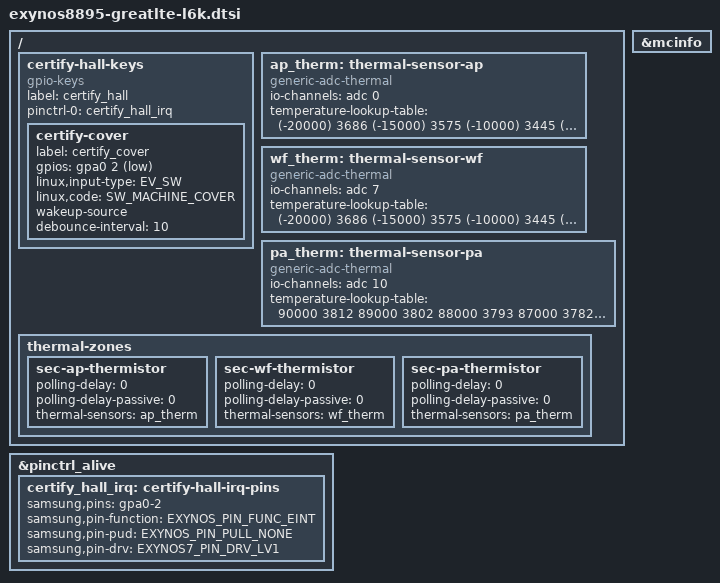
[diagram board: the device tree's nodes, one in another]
// SPDX-License-Identifier: GPL-2.0 OR BSD-3-Clause
/*
 * Samsung Galaxy Note 8 (greatlte, SM-N950N) board DT, part "l6k":
 * L6K misc I/O: certify hall, DRAM temperature trip, AP/WF/PA thermistors (L6K 4).
 *
 * Included at the end of exynos8895-greatlte.dts, after L0's nodes, in the merge
 * order of FULL_IMAGE_PLAN.md 2.2. Owner: WP-6K; no other work package edits this
 * file (plan 2.3 rule D1). A node that two parts both configure (&usi9, &usi10)
 * is written identically in both files: dtc lets the later file win on a differing
 * value, which gl-verify V-DUP reports as an error. L0's reserved-memory stays in
 * the .dts; carveout additions and flag changes are &label edits here (plan X-8).
 */

#include <dt-bindings/gpio/gpio.h>
#include <dt-bindings/input/input.h>		/* EV_SW, SW_MACHINE_COVER, 4.1 */
#include "exynos-pinctrl.h"			/* A:arch/arm64/boot/dts/exynos/exynos-pinctrl.h, pin macros of 4.1 */

/* L6K 4.1 certify hall (stock certify_hall FDT:11210-11216, D-1) */
&pinctrl_alive {
	certify_hall_irq: certify-hall-irq-pins {	/* FDT:257-263 (phandle 0x143) */
		samsung,pins = "gpa0-2";
		samsung,pin-function = <EXYNOS_PIN_FUNC_EINT>;	/* 0x0f; A:arch/arm64/boot/dts/exynos/exynos-pinctrl.h:76 */
		samsung,pin-pud = <EXYNOS_PIN_PULL_NONE>;	/* 0x00; :14 */
		samsung,pin-drv = <EXYNOS7_PIN_DRV_LV1>;	/* 0x00; :48 */
	};
};

/ {
	certify-hall-keys {
		compatible = "gpio-keys";
		label = "certify_hall";			/* stock input name S:drivers/input/certify_hall.c:249;
							   gpio-keys uses the label as input name, A:drivers/input/keyboard/gpio_keys.c:778,879 */
		pinctrl-names = "default";
		pinctrl-0 = <&certify_hall_irq>;	/* FDT:11213-11214 <0x143> */

		certify-cover {
			label = "certify_cover";
			gpios = <&gpa0 2 GPIO_ACTIVE_LOW>;	/* FDT:11215 <0x90 2 0>; attached = level 0
								   (S:drivers/input/certify_hall.c:95,127) */
			linux,input-type = <EV_SW>;		/* A:drivers/input/keyboard/gpio_keys.c:803 */
			linux,code = <SW_MACHINE_COVER>;	/* 0x10 A:include/uapi/linux/input-event-codes.h:952;
								   stock SW_CERTIFYHALL 0x1b > SW_MAX 0x11 (:954), D-1 */
			wakeup-source;				/* stock arms the wake at every suspend,
								   S:drivers/input/certify_hall.c:337; A:.../gpio_keys.c:811 */
			debounce-interval = <10>;		/* stock attach delay HZ*1/100 "10ms" (S:.../certify_hall.c:114);
								   = 2 jiffies = 8 ms at HZ 250 (IKC:448); 10 = the tree's
								   convention for this expression (L6F hall-keys);
								   A:.../gpio_keys.c:821 */
		};
	};
};

/* L6K 4.2 DRAM temperature trip (SoC node in exynos8895.dtsi) */
&mcinfo {
	status = "okay";
};

/* L6K 4.3 AP/WF/PA thermistors (stock sec_thermistor@0/@7/@10 FDT:11172-11200, D-3) */
/ {
	ap_therm: thermal-sensor-ap {
		compatible = "generic-adc-thermal";		/* A:drivers/thermal/thermal-generic-adc.c (lookup :27-56) */
		#thermal-sensor-cells = <0>;
		io-channels = <&adc 0>;				/* FDT:11177 <0x141 0x00> "adc-ap-temp" */
		io-channel-names = "sensor-channel";
		/* FDT:11175-11176, x100 to milli-degC, code falling (= L6F battery table, FDT:12188-12189) */
		temperature-lookup-table = <
			(-20000) 3686	(-15000) 3575	(-10000) 3445	(-5000) 3293
			0 3122		5000 2932	10000 2726	15000 2512
			20000 2291	25000 2048	30000 1811	35000 1586
			40000 1378	45000 1189	50000 1021	55000 887
			60000 769	65000 655	70000 558	75000 474
			80000 404	85000 345	90000 294 >;
	};

	wf_therm: thermal-sensor-wf {
		compatible = "generic-adc-thermal";
		#thermal-sensor-cells = <0>;
		io-channels = <&adc 7>;				/* FDT:11187 <0x141 0x07> "adc-wf-temp" */
		io-channel-names = "sensor-channel";
		/* FDT:11185-11186, identical to the AP table */
		temperature-lookup-table = <
			(-20000) 3686	(-15000) 3575	(-10000) 3445	(-5000) 3293
			0 3122		5000 2932	10000 2726	15000 2512
			20000 2291	25000 2048	30000 1811	35000 1586
			40000 1378	45000 1189	50000 1021	55000 887
			60000 769	65000 655	70000 558	75000 474
			80000 404	85000 345	90000 294 >;
	};

	pa_therm: thermal-sensor-pa {
		compatible = "generic-adc-thermal";
		#thermal-sensor-cells = <0>;
		io-channels = <&adc 10>;			/* FDT:11197 <0x141 0x0a> "adc-pa-temp" */
		io-channel-names = "sensor-channel";
		/* FDT:11195-11196: 111 points, code RISES with temperature; sorted by code falling, which
		 * gadc_thermal_adc_to_temp() requires (first entry with val >= code, A:...:35-38); the
		 * interpolation (:45-52) is direction-agnostic, and out-of-range codes clamp to the end
		 * points (:40-43) = stock's clamps (S:drivers/hwmon/sec_thermistor.c:175-178) */
		temperature-lookup-table = <
			90000 3812 89000 3802 88000 3793 87000 3782 86000 3773 85000 3761 84000 3752 83000 3741
			82000 3730 81000 3716 80000 3705 79000 3691 78000 3680 77000 3666 76000 3650 75000 3636
			74000 3620 73000 3607 72000 3591 71000 3573 70000 3557 69000 3538 68000 3520 67000 3502
			66000 3482 65000 3461 64000 3441 63000 3420 62000 3397 61000 3375 60000 3352 59000 3327
			58000 3302 57000 3277 56000 3249 55000 3222 54000 3195 53000 3165 52000 3136 51000 3106
			50000 3074 49000 3042 48000 3011 47000 2976 46000 2942 45000 2906 44000 2872 43000 2833
			42000 2797 41000 2758 40000 2719 39000 2678 38000 2637 37000 2596 36000 2553 35000 2510
			34000 2467 33000 2421 32000 2378 31000 2332 30000 2285 29000 2239 28000 2192 27000 2144
			26000 2096 25000 2048 24000 2000 23000 1951 22000 1902 21000 1853 20000 1804 19000 1755
			18000 1706 17000 1657 16000 1608 15000 1559 14000 1511 13000 1463 12000 1416 11000 1369
			10000 1323 9000 1277 8000 1231 7000 1187 6000 1143 5000 1100 4000 1057 3000 1016
			2000 975 1000 935 0 896 (-1000) 858 (-2000) 821 (-3000) 786 (-4000) 750 (-5000) 717
			(-6000) 684 (-7000) 651 (-8000) 621 (-9000) 591 (-10000) 562 (-11000) 534 (-12000) 507
			(-13000) 482 (-14000) 456 (-15000) 433 (-16000) 410 (-17000) 388 (-18000) 367 (-19000) 347
			(-20000) 327 >;
	};

	thermal-zones {
		/* zone type = node name (A:drivers/thermal/thermal_of.c:415), <= THERMAL_NAME_LENGTH 20
		 * (A:include/uapi/linux/thermal.h:5); stock sec device names (S:drivers/hwmon/sec_thermistor.c:55-60) */
		sec-ap-thermistor {
			polling-delay = <0>;		/* stock reads only on demand (S:drivers/hwmon/sec_thermistor.c:132-159) */
			polling-delay-passive = <0>;
			thermal-sensors = <&ap_therm>;
			/* no trips (stock had none): "No trip points found" A:drivers/thermal/thermal_of.c:395 */
		};

		sec-wf-thermistor {
			polling-delay = <0>;
			polling-delay-passive = <0>;
			thermal-sensors = <&wf_therm>;
		};

		sec-pa-thermistor {
			polling-delay = <0>;
			polling-delay-passive = <0>;
			thermal-sensors = <&pa_therm>;
		};
	};
};
